# nrf52840 register map
Vendor: Nordic Semiconductor; Series: nrf52; File version: 1
CPU: CM4 r0p1, little endian, MPU, FPU, 3 interrupt priority bits
Registers are 32-bit, read-write, reset 0x0 unless marked. A register's access mark holds for its fields unless they carry their own. Offsets are from the block's base; [hi:lo] are bit positions; lines under a group give offsets from that group; {n}, {i} and the like mark numbered series; 'fields as' and 'values as' point back to an identical list.

## SAADC — Successive approximation register (SAR) analog-to-digital converter
Base 0x40007000
0x00 TASKS_START wo — Starts the SAADC and prepares the result buffer in RAM
  [0] TASKS_START
    1=Trigger task
0x04 TASKS_SAMPLE wo — Takes one SAADC sample
  [0] TASKS_SAMPLE
    1=Trigger task
0x08 TASKS_STOP wo — Stops the SAADC and terminates all on-going conversions
  [0] TASKS_STOP
    1=Trigger task
0x0C TASKS_CALIBRATEOFFSET wo — Starts offset auto-calibration
  [0] TASKS_CALIBRATEOFFSET
    1=Trigger task
0x100 EVENTS_STARTED — The SAADC has started
  [0] EVENTS_STARTED
    0=NotGenerated (Event not generated); 1=Generated (Event generated)
0x104 EVENTS_END — The SAADC has filled up the result buffer
  [0] EVENTS_END
    values as EVENTS_STARTED.EVENTS_STARTED
0x108 EVENTS_DONE — A conversion task has been completed. Depending on the configuration, multiple conversions might be needed for a result to be transferred to RAM.
  [0] EVENTS_DONE
    values as EVENTS_STARTED.EVENTS_STARTED
0x10C EVENTS_RESULTDONE — Result ready for transfer to RAM
  [0] EVENTS_RESULTDONE
    values as EVENTS_STARTED.EVENTS_STARTED
0x110 EVENTS_CALIBRATEDONE — Calibration is complete
  [0] EVENTS_CALIBRATEDONE
    values as EVENTS_STARTED.EVENTS_STARTED
0x114 EVENTS_STOPPED — The SAADC has stopped
  [0] EVENTS_STOPPED
    values as EVENTS_STARTED.EVENTS_STARTED
{0x118+8i} EVENTS_CH[{i}] (i=0..7) group — Peripheral events.
  0x00 LIMITH — Description cluster: Last result is equal or above CH[n].LIMIT.HIGH
    [0] LIMITH — Last result is equal or above CH[n].LIMIT.HIGH
      values as EVENTS_STARTED.EVENTS_STARTED
  0x04 LIMITL — Description cluster: Last result is equal or below CH[n].LIMIT.LOW
    [0] LIMITL — Last result is equal or below CH[n].LIMIT.LOW
      values as EVENTS_STARTED.EVENTS_STARTED
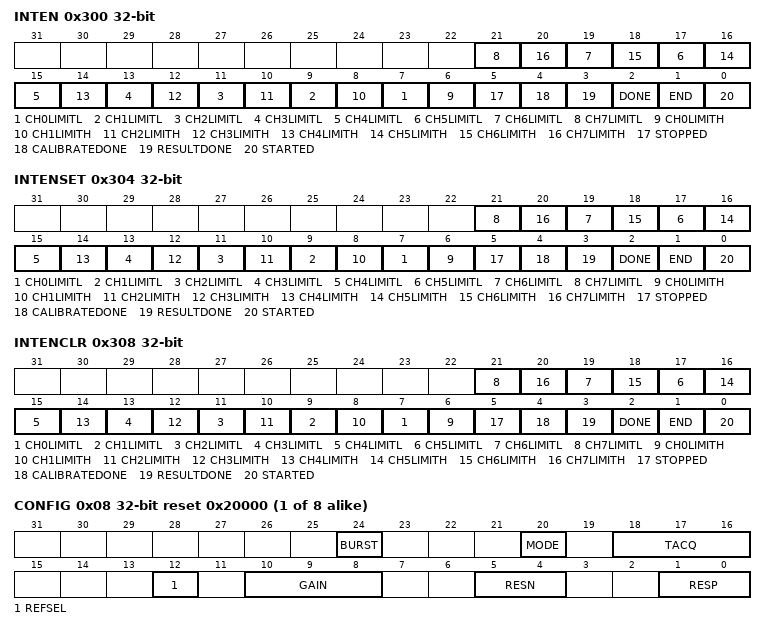
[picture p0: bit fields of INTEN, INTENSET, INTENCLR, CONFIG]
0x300 INTEN — Enable or disable interrupt
  [all] fields
    0=Disabled; 1=Enabled
  [2n+7] CH{n}LIMITL (n=0..7) — Enable or disable interrupt for event CH{n}LIMITL
  [2n+6] CH{n}LIMITH (n=0..7) — Enable or disable interrupt for event CH{n}LIMITH
  [5] STOPPED — Enable or disable interrupt for event STOPPED
  [4] CALIBRATEDONE — Enable or disable interrupt for event CALIBRATEDONE
  [3] RESULTDONE — Enable or disable interrupt for event RESULTDONE
  [2] DONE — Enable or disable interrupt for event DONE
  [1] END — Enable or disable interrupt for event END
  [0] STARTED — Enable or disable interrupt for event STARTED
0x304 INTENSET — Enable interrupt
  [all] fields
    on read: 0=Disabled (Read: Disabled); 1=Enabled (Read: Enabled) | on write: 1=Set (Enable)
  [2n+7] CH{n}LIMITL (n=0..7) — Write '1' to enable interrupt for event CH{n}LIMITL
  [2n+6] CH{n}LIMITH (n=0..7) — Write '1' to enable interrupt for event CH{n}LIMITH
  [5] STOPPED — Write '1' to enable interrupt for event STOPPED
  [4] CALIBRATEDONE — Write '1' to enable interrupt for event CALIBRATEDONE
  [3] RESULTDONE — Write '1' to enable interrupt for event RESULTDONE
  [2] DONE — Write '1' to enable interrupt for event DONE
  [1] END — Write '1' to enable interrupt for event END
  [0] STARTED — Write '1' to enable interrupt for event STARTED
0x308 INTENCLR — Disable interrupt
  [all] fields
    on read: 0=Disabled (Read: Disabled); 1=Enabled (Read: Enabled) | on write: 1=Clear (Disable)
  [2n+7] CH{n}LIMITL (n=0..7) — Write '1' to disable interrupt for event CH{n}LIMITL
  [2n+6] CH{n}LIMITH (n=0..7) — Write '1' to disable interrupt for event CH{n}LIMITH
  [5] STOPPED — Write '1' to disable interrupt for event STOPPED
  [4] CALIBRATEDONE — Write '1' to disable interrupt for event CALIBRATEDONE
  [3] RESULTDONE — Write '1' to disable interrupt for event RESULTDONE
  [2] DONE — Write '1' to disable interrupt for event DONE
  [1] END — Write '1' to disable interrupt for event END
  [0] STARTED — Write '1' to disable interrupt for event STARTED
0x400 STATUS ro
  [0] STATUS
    0=Ready (SAADC is ready. No on-going conversions.); 1=Busy (SAADC is busy. Conversion in progress.)
0x500 ENABLE — Enable or disable SAADC
  [0] ENABLE
    0=Disabled (Disable SAADC); 1=Enabled (Enable SAADC)
{0x510+0x10*i} CH[{i}] (i=0..7) group — Unspecified
  0x00 PSELP — Description cluster: Input positive pin selection for CH[n]
    [4:0] PSELP — Analog positive input channel
      0=NC (Not connected); {v}=AnalogInput{v-1} (AIN{v-1}) (v=1..8); 9=VDD; 13=VDDHDIV5 (VDDH/5)
  0x04 PSELN — Description cluster: Input negative pin selection for CH[n]
    [4:0] PSELN — Analog negative input, enables differential channel
      values as CH[0].PSELP.PSELP
  0x08 CONFIG reset 0x20000 — Description cluster: Input configuration for CH[n]
    [24] BURST — Enable burst mode
      0=Disabled (Burst mode is disabled (normal operation)); 1=Enabled (Burst mode is enabled. SAADC takes 2^OVERSAMPLE number of samples as fast as it can, and sends the average to Data RAM.)
    [20] MODE — Enable differential mode
      0=SE (Single-ended, PSELN will be ignored, negative input to SAADC shorted to GND); 1=Differential
    [18:16] TACQ — Acquisition time, the time the SAADC uses to sample the input voltage
      0=3us; 1=5us; 2=10us; 3=15us; 4=20us; 5=40us
    [12] REFSEL — Reference control
      0=Internal reference (0.6 V); 1=VDD1_4 (VDD/4 as reference)
    [10:8] GAIN — Gain control
      0=Gain1_6 (1/6); 1=Gain1_5 (1/5); 2=Gain1_4 (1/4); 3=Gain1_3 (1/3); 4=Gain1_2 (1/2); 5=1; 6=2; 7=4
    [5:4] RESN — Negative channel resistor control
      0=Bypass resistor ladder; 1=Pull-down to GND; 2=Pull-up to VDD; 3=VDD1_2 (Set input at VDD/2)
    [1:0] RESP — Positive channel resistor control
      values as RESN
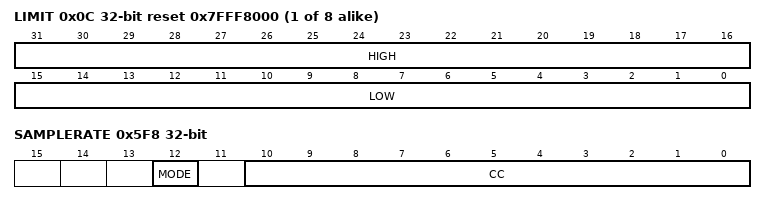
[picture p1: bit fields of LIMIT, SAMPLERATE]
  0x0C LIMIT reset 0x7FFF8000 — Description cluster: High/low limits for event monitoring of a channel
    [31:16] HIGH — High level limit
    [15:0] LOW — Low level limit
0x5F0 RESOLUTION reset 0x1 — Resolution configuration
  [2:0] VAL — Set the resolution
    0=8 bits; 1=10 bits; 2=12 bits; 3=14 bits
0x5F4 OVERSAMPLE — Oversampling configuration. The RESOLUTION is applied before averaging, thus for high OVERSAMPLE a higher RESOLUTION should be used.
  [3:0] OVERSAMPLE — Oversample control
    0=Bypass oversampling; 1=Over2x (Oversample 2x); 2=Over4x (Oversample 4x); 3=Over8x (Oversample 8x); 4=Over16x (Oversample 16x); 5=Over32x (Oversample 32x); 6=Over64x (Oversample 64x); 7=Over128x (Oversample 128x); 8=Over256x (Oversample 256x)
0x5F8 SAMPLERATE — Controls normal or continuous sample rate
  [12] MODE — Select mode for sample rate control
    0=Task (Rate is controlled from SAMPLE task); 1=Timers (Rate is controlled from local timer (use CC to control the rate))
  [10:0] CC — Capture and compare value. Sample rate is 16 MHz/CC
0x62C RESULT group — RESULT EasyDMA channel
  0x00 PTR — Data pointer
  0x04 MAXCNT — Maximum number of 16-bit samples to be written to output RAM buffer
    [14:0] MAXCNT
  0x08 AMOUNT ro — Number of 16-bit samples written to output RAM buffer since the previous START task
    [14:0] AMOUNT — Number of 16-bit samples written to output RAM buffer since the previous START task. This register can be read after an END or STOPPED event.

## Notices in the file
Copyright (c) 2010 - 2020, Nordic Semiconductor ASA All rights reserved.
Redistribution and use in source and binary forms, with or without
modification, are permitted provided that the following conditions are met:
1. Redistributions of source code must retain the above copyright notice, this
list of conditions and the following disclaimer.
2. Redistributions in binary form must reproduce the above copyright
notice, this list of conditions and the following disclaimer in the
documentation and/or other materials provided with the distribution.
3. Neither the name of Nordic Semiconductor ASA nor the names of its
contributors may be used to endorse or promote products derived from this
software without specific prior written permission.
THIS SOFTWARE IS PROVIDED BY THE COPYRIGHT HOLDERS AND CONTRIBUTORS "AS IS"
AND ANY EXPRESS OR IMPLIED WARRANTIES, INCLUDING, BUT NOT LIMITED TO, THE
IMPLIED WARRANTIES OF MERCHANTABILITY, AND FITNESS FOR A PARTICULAR PURPOSE
ARE DISCLAIMED. IN NO EVENT SHALL NORDIC SEMICONDUCTOR ASA OR CONTRIBUTORS BE
LIABLE FOR ANY DIRECT, INDIRECT, INCIDENTAL, SPECIAL, EXEMPLARY, OR
CONSEQUENTIAL DAMAGES (INCLUDING, BUT NOT LIMITED TO, PROCUREMENT OF
SUBSTITUTE GOODS OR SERVICES; LOSS OF USE, DATA, OR PROFITS; OR BUSINESS
INTERRUPTION) HOWEVER CAUSED AND ON ANY THEORY OF LIABILITY, WHETHER IN
CONTRACT, STRICT LIABILITY, OR TORT (INCLUDING NEGLIGENCE OR OTHERWISE)
ARISING IN ANY WAY OUT OF THE USE OF THIS SOFTWARE, EVEN IF ADVISED OF THE
POSSIBILITY OF SUCH DAMAGE.
